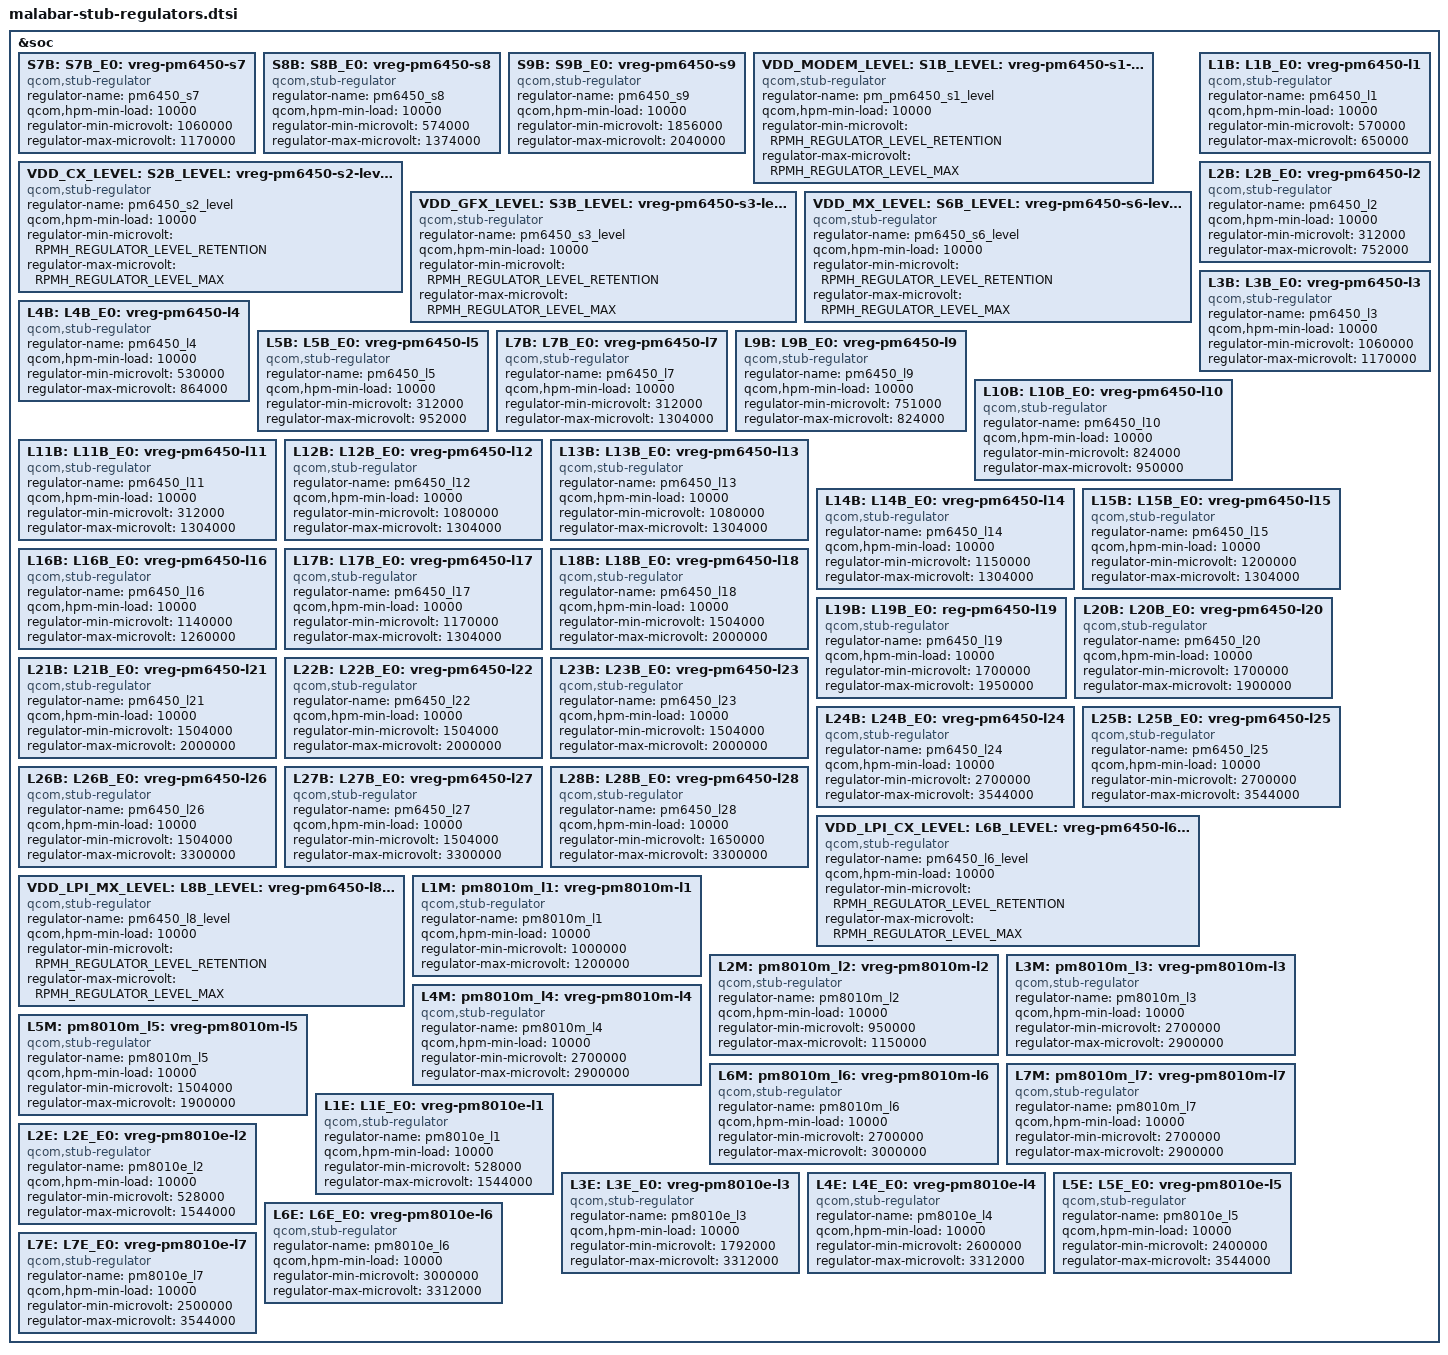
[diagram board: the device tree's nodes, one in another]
// SPDX-License-Identifier: BSD-3-Clause
/*
 * Copyright (c) Qualcomm Technologies, Inc. and/or its subsidiaries.
 */

#include <dt-bindings/regulator/qcom,rpmh-regulator-levels.h>

&soc {
		S7B:
		S7B_E0:
		pm6450_s7: vreg-pm6450-s7 {
			compatible = "qcom,stub-regulator";
			regulator-name = "pm6450_s7";
			qcom,hpm-min-load = <10000>;
			regulator-min-microvolt = <1060000>;
			regulator-max-microvolt = <1170000>;
		};

		S8B:
		S8B_E0:
		pm6450_s8: vreg-pm6450-s8 {
			compatible = "qcom,stub-regulator";
			regulator-name = "pm6450_s8";
			qcom,hpm-min-load = <10000>;
			regulator-min-microvolt = <574000>;
			regulator-max-microvolt = <1374000>;
		};

		S9B:
		S9B_E0:
		pm6450_s9: vreg-pm6450-s9 {
			compatible = "qcom,stub-regulator";
			regulator-name = "pm6450_s9";
			qcom,hpm-min-load = <10000>;
			regulator-min-microvolt = <1856000>;
			regulator-max-microvolt = <2040000>;
		};

		VDD_MODEM_LEVEL:
		S1B_LEVEL:
		S1B_E0_LEVEL:
		pm6450_s1_level: vreg-pm6450-s1-level {
			compatible = "qcom,stub-regulator";
			regulator-name = "pm_pm6450_s1_level";
			qcom,hpm-min-load = <10000>;
			regulator-min-microvolt =
				<RPMH_REGULATOR_LEVEL_RETENTION>;
			regulator-max-microvolt = <RPMH_REGULATOR_LEVEL_MAX>;
		};

		VDD_CX_LEVEL:
		S2B_LEVEL:
		S2B_E0_LEVEL:
		VDD_CX_LEVEL_AO:
		S2B_LEVEL_AO:
		S2B_E0_LEVEL_A0:
		pm6450_s2_level: vreg-pm6450-s2-level {
			compatible = "qcom,stub-regulator";
			regulator-name = "pm6450_s2_level";
			qcom,hpm-min-load = <10000>;
			regulator-min-microvolt =
				<RPMH_REGULATOR_LEVEL_RETENTION>;
			regulator-max-microvolt = <RPMH_REGULATOR_LEVEL_MAX>;
		};

		VDD_GFX_LEVEL:
		S3B_LEVEL:
		S3B_E0_LEVEL:
		pm6450_s3_level: vreg-pm6450-s3-level {
			compatible = "qcom,stub-regulator";
			regulator-name = "pm6450_s3_level";
			qcom,hpm-min-load = <10000>;
			regulator-min-microvolt =
				<RPMH_REGULATOR_LEVEL_RETENTION>;
			regulator-max-microvolt = <RPMH_REGULATOR_LEVEL_MAX>;
		};

		VDD_MX_LEVEL:
		S6B_LEVEL:
		S6B_E0_LEVEL:
		VDD_MX_LEVEL_AO:
		S6B_LEVEL_AO:
		pm6450_s6_level: vreg-pm6450-s6-level {
			compatible = "qcom,stub-regulator";
			regulator-name = "pm6450_s6_level";
			qcom,hpm-min-load = <10000>;
			regulator-min-microvolt =
				<RPMH_REGULATOR_LEVEL_RETENTION>;
			regulator-max-microvolt = <RPMH_REGULATOR_LEVEL_MAX>;
		};

		L1B:
		L1B_E0:
		pm6450_l1: vreg-pm6450-l1 {
			compatible = "qcom,stub-regulator";
			regulator-name = "pm6450_l1";
			qcom,hpm-min-load = <10000>;
			regulator-min-microvolt = <570000>;
			regulator-max-microvolt = <650000>;
		};

		L2B:
		L2B_E0:
		pm6450_l2: vreg-pm6450-l2 {
			compatible = "qcom,stub-regulator";
			regulator-name = "pm6450_l2";
			qcom,hpm-min-load = <10000>;
			regulator-min-microvolt = <312000>;
			regulator-max-microvolt = <752000>;
		};

		L3B:
		L3B_E0:
		pm6450_l3: vreg-pm6450-l3 {
			compatible = "qcom,stub-regulator";
			regulator-name = "pm6450_l3";
			qcom,hpm-min-load = <10000>;
			regulator-min-microvolt = <1060000>;
			regulator-max-microvolt = <1170000>;
		};

		L4B:
		L4B_E0:
		pm6450_l4: vreg-pm6450-l4 {
			compatible = "qcom,stub-regulator";
			regulator-name = "pm6450_l4";
			qcom,hpm-min-load = <10000>;
			regulator-min-microvolt = <530000>;
			regulator-max-microvolt = <864000>;
		};

		L5B:
		L5B_E0:
		pm6450_l5: vreg-pm6450-l5 {
			compatible = "qcom,stub-regulator";
			regulator-name = "pm6450_l5";
			qcom,hpm-min-load = <10000>;
			regulator-min-microvolt = <312000>;
			regulator-max-microvolt = <952000>;
		};

		L7B:
		L7B_E0:
		pm6450_l7: vreg-pm6450-l7 {
			compatible = "qcom,stub-regulator";
			regulator-name = "pm6450_l7";
			qcom,hpm-min-load = <10000>;
			regulator-min-microvolt = <312000>;
			regulator-max-microvolt = <1304000>;
		};

		L9B:
		L9B_E0:
		pm6450_l9: vreg-pm6450-l9 {
			compatible = "qcom,stub-regulator";
			regulator-name = "pm6450_l9";
			qcom,hpm-min-load = <10000>;
			regulator-min-microvolt = <751000>;
			regulator-max-microvolt = <824000>;
		};

		L10B:
		L10B_E0:
		pm6450_l10: vreg-pm6450-l10 {
			compatible = "qcom,stub-regulator";
			regulator-name = "pm6450_l10";
			qcom,hpm-min-load = <10000>;
			regulator-min-microvolt = <824000>;
			regulator-max-microvolt = <950000>;
		};

		L11B:
		L11B_E0:
		pm6450_l11: vreg-pm6450-l11 {
			compatible = "qcom,stub-regulator";
			regulator-name = "pm6450_l11";
			qcom,hpm-min-load = <10000>;
			regulator-min-microvolt = <312000>;
			regulator-max-microvolt = <1304000>;
		};

		L12B:
		L12B_E0:
		pm6450_l12: vreg-pm6450-l12 {
			compatible = "qcom,stub-regulator";
			regulator-name = "pm6450_l12";
			qcom,hpm-min-load = <10000>;
			regulator-min-microvolt = <1080000>;
			regulator-max-microvolt = <1304000>;
		};

		L13B:
		L13B_E0:
		pm6450_l13: vreg-pm6450-l13 {
			compatible = "qcom,stub-regulator";
			regulator-name = "pm6450_l13";
			qcom,hpm-min-load = <10000>;
			regulator-min-microvolt = <1080000>;
			regulator-max-microvolt = <1304000>;
		};

		L14B:
		L14B_E0:
		pm6450_l14: vreg-pm6450-l14 {
			compatible = "qcom,stub-regulator";
			regulator-name = "pm6450_l14";
			qcom,hpm-min-load = <10000>;
			regulator-min-microvolt = <1150000>;
			regulator-max-microvolt = <1304000>;
		};

		L15B:
		L15B_E0:
		pm6450_l15: vreg-pm6450-l15 {
			compatible = "qcom,stub-regulator";
			regulator-name = "pm6450_l15";
			qcom,hpm-min-load = <10000>;
			regulator-min-microvolt = <1200000>;
			regulator-max-microvolt = <1304000>;
		};

		L16B:
		L16B_E0:
		pm6450_l16: vreg-pm6450-l16 {
			compatible = "qcom,stub-regulator";
			regulator-name = "pm6450_l16";
			qcom,hpm-min-load = <10000>;
			regulator-min-microvolt = <1140000>;
			regulator-max-microvolt = <1260000>;
		};

		L17B:
		L17B_E0:
		pm6450_l17: vreg-pm6450-l17 {
			compatible = "qcom,stub-regulator";
			regulator-name = "pm6450_l17";
			qcom,hpm-min-load = <10000>;
			regulator-min-microvolt = <1170000>;
			regulator-max-microvolt = <1304000>;
		};

		L18B:
		L18B_E0:
		pm6450_l18: vreg-pm6450-l18 {
			compatible = "qcom,stub-regulator";
			regulator-name = "pm6450_l18";
			qcom,hpm-min-load = <10000>;
			regulator-min-microvolt = <1504000>;
			regulator-max-microvolt = <2000000>;
		};

		L19B:
		L19B_E0:
		pm6450_l19: reg-pm6450-l19 {
			compatible = "qcom,stub-regulator";
			regulator-name = "pm6450_l19";
			qcom,hpm-min-load = <10000>;
			regulator-min-microvolt = <1700000>;
			regulator-max-microvolt = <1950000>;
		};

		L20B:
		L20B_E0:
		pm6450_l20: vreg-pm6450-l20 {
			compatible = "qcom,stub-regulator";
			regulator-name = "pm6450_l20";
			qcom,hpm-min-load = <10000>;
			regulator-min-microvolt = <1700000>;
			regulator-max-microvolt = <1900000>;
		};

		L21B:
		L21B_E0:
		pm6450_l21: vreg-pm6450-l21 {
			compatible = "qcom,stub-regulator";
			regulator-name = "pm6450_l21";
			qcom,hpm-min-load = <10000>;
			regulator-min-microvolt = <1504000>;
			regulator-max-microvolt = <2000000>;
		};

		L22B:
		L22B_E0:
		pm6450_l22: vreg-pm6450-l22 {
			compatible = "qcom,stub-regulator";
			regulator-name = "pm6450_l22";
			qcom,hpm-min-load = <10000>;
			regulator-min-microvolt = <1504000>;
			regulator-max-microvolt = <2000000>;
		};

		L23B:
		L23B_E0:
		pm6450_l23: vreg-pm6450-l23 {
			compatible = "qcom,stub-regulator";
			regulator-name = "pm6450_l23";
			qcom,hpm-min-load = <10000>;
			regulator-min-microvolt = <1504000>;
			regulator-max-microvolt = <2000000>;
		};

		L24B:
		L24B_E0:
		pm6450_l24: vreg-pm6450-l24 {
			compatible = "qcom,stub-regulator";
			regulator-name = "pm6450_l24";
			qcom,hpm-min-load = <10000>;
			regulator-min-microvolt = <2700000>;
			regulator-max-microvolt = <3544000>;
		};

		L25B:
		L25B_E0:
		pm6450_l25: vreg-pm6450-l25 {
			compatible = "qcom,stub-regulator";
			regulator-name = "pm6450_l25";
			qcom,hpm-min-load = <10000>;
			regulator-min-microvolt = <2700000>;
			regulator-max-microvolt = <3544000>;
		};

		L26B:
		L26B_E0:
		pm6450_l26: vreg-pm6450-l26 {
			compatible = "qcom,stub-regulator";
			regulator-name = "pm6450_l26";
			qcom,hpm-min-load = <10000>;
			regulator-min-microvolt = <1504000>;
			regulator-max-microvolt = <3300000>;
		};

		L27B:
		L27B_E0:
		pm6450_l27: vreg-pm6450-l27 {
			compatible = "qcom,stub-regulator";
			regulator-name = "pm6450_l27";
			qcom,hpm-min-load = <10000>;
			regulator-min-microvolt = <1504000>;
			regulator-max-microvolt = <3300000>;
		};

		L28B:
		L28B_E0:
		pm6450_l28: vreg-pm6450-l28 {
			compatible = "qcom,stub-regulator";
			regulator-name = "pm6450_l28";
			qcom,hpm-min-load = <10000>;
			regulator-min-microvolt = <1650000>;
			regulator-max-microvolt = <3300000>;
		};

		VDD_LPI_CX_LEVEL:
		L6B_LEVEL:
		L6B_E0_LEVEL:
		pm6450_l6_level: vreg-pm6450-l6-level {
			compatible = "qcom,stub-regulator";
			regulator-name = "pm6450_l6_level";
			qcom,hpm-min-load = <10000>;
			regulator-min-microvolt =
				<RPMH_REGULATOR_LEVEL_RETENTION>;
			regulator-max-microvolt = <RPMH_REGULATOR_LEVEL_MAX>;
		};

		VDD_LPI_MX_LEVEL:
		L8B_LEVEL:
		L8B_E0_LEVEL:
		pm6450_l8_level: vreg-pm6450-l8-level {
			compatible = "qcom,stub-regulator";
			regulator-name = "pm6450_l8_level";
			qcom,hpm-min-load = <10000>;
			regulator-min-microvolt =
				<RPMH_REGULATOR_LEVEL_RETENTION>;
			regulator-max-microvolt = <RPMH_REGULATOR_LEVEL_MAX>;
		};

		L1M:
		pm8010m_l1: vreg-pm8010m-l1 {
			compatible = "qcom,stub-regulator";
			regulator-name = "pm8010m_l1";
			qcom,hpm-min-load = <10000>;
			regulator-min-microvolt = <1000000>;
			regulator-max-microvolt = <1200000>;
		};

		L2M:
		pm8010m_l2: vreg-pm8010m-l2 {
			compatible = "qcom,stub-regulator";
			regulator-name = "pm8010m_l2";
			qcom,hpm-min-load = <10000>;
			regulator-min-microvolt = <950000>;
			regulator-max-microvolt = <1150000>;
		};

		L3M:
		pm8010m_l3: vreg-pm8010m-l3 {
			compatible = "qcom,stub-regulator";
			regulator-name = "pm8010m_l3";
			qcom,hpm-min-load = <10000>;
			regulator-min-microvolt = <2700000>;
			regulator-max-microvolt = <2900000>;
		};

		L4M:
		pm8010m_l4: vreg-pm8010m-l4 {
			compatible = "qcom,stub-regulator";
			regulator-name = "pm8010m_l4";
			qcom,hpm-min-load = <10000>;
			regulator-min-microvolt = <2700000>;
			regulator-max-microvolt = <2900000>;
		};

		L5M:
		pm8010m_l5: vreg-pm8010m-l5 {
			compatible = "qcom,stub-regulator";
			regulator-name = "pm8010m_l5";
			qcom,hpm-min-load = <10000>;
			regulator-min-microvolt = <1504000>;
			regulator-max-microvolt = <1900000>;
		};

		L6M:
		pm8010m_l6: vreg-pm8010m-l6 {
			compatible = "qcom,stub-regulator";
			regulator-name = "pm8010m_l6";
			qcom,hpm-min-load = <10000>;
			regulator-min-microvolt = <2700000>;
			regulator-max-microvolt = <3000000>;
		};

		L7M:
		pm8010m_l7: vreg-pm8010m-l7 {
			compatible = "qcom,stub-regulator";
			regulator-name = "pm8010m_l7";
			qcom,hpm-min-load = <10000>;
			regulator-min-microvolt = <2700000>;
			regulator-max-microvolt = <2900000>;
		};

		L1E:
		L1E_E0:
		pm8010e_l1: vreg-pm8010e-l1 {
			compatible = "qcom,stub-regulator";
			regulator-name = "pm8010e_l1";
			qcom,hpm-min-load = <10000>;
			regulator-min-microvolt = <528000>;
			regulator-max-microvolt = <1544000>;
		};

		L2E:
		L2E_E0:
		pm8010e_l2: vreg-pm8010e-l2 {
			compatible = "qcom,stub-regulator";
			regulator-name = "pm8010e_l2";
			qcom,hpm-min-load = <10000>;
			regulator-min-microvolt = <528000>;
			regulator-max-microvolt = <1544000>;
		};

		L3E:
		L3E_E0:
		pm8010e_l3: vreg-pm8010e-l3 {
			compatible = "qcom,stub-regulator";
			regulator-name = "pm8010e_l3";
			qcom,hpm-min-load = <10000>;
			regulator-min-microvolt = <1792000>;
			regulator-max-microvolt = <3312000>;
		};

		L4E:
		L4E_E0:
		pm8010e_l4: vreg-pm8010e-l4 {
			compatible = "qcom,stub-regulator";
			regulator-name = "pm8010e_l4";
			qcom,hpm-min-load = <10000>;
			regulator-min-microvolt = <2600000>;
			regulator-max-microvolt = <3312000>;
		};

		L5E:
		L5E_E0:
		pm8010e_l5: vreg-pm8010e-l5 {
			compatible = "qcom,stub-regulator";
			regulator-name = "pm8010e_l5";
			qcom,hpm-min-load = <10000>;
			regulator-min-microvolt = <2400000>;
			regulator-max-microvolt = <3544000>;
		};

		L6E:
		L6E_E0:
		pm8010e_l6: vreg-pm8010e-l6 {
			compatible = "qcom,stub-regulator";
			regulator-name = "pm8010e_l6";
			qcom,hpm-min-load = <10000>;
			regulator-min-microvolt = <3000000>;
			regulator-max-microvolt = <3312000>;
		};

		L7E:
		L7E_E0:
		pm8010e_l7: vreg-pm8010e-l7 {
			compatible = "qcom,stub-regulator";
			regulator-name = "pm8010e_l7";
			qcom,hpm-min-load = <10000>;
			regulator-min-microvolt = <2500000>;
			regulator-max-microvolt = <3544000>;
		};
};
